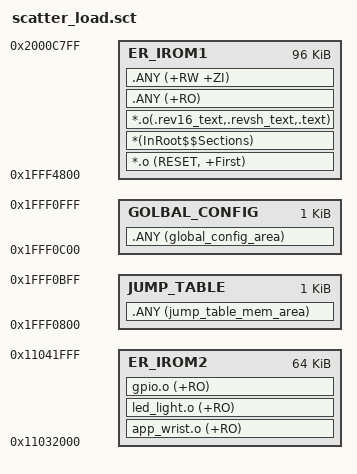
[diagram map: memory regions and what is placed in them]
; *************************************************************
; *** Scatter-Loading Description File generated by uVision ***
; *************************************************************

 LR_IROM1 0x1fff4800 0x00018000 {  ; load region size_region
  ER_IROM1 0x1fff4800 0x00018000  {  ; load address = execution address
   *.o (RESET, +First)
   *(InRoot$$Sections)
   *.o(.rev16_text,.revsh_text,.text)
   .ANY (+RO) 
   .ANY (+RW +ZI)
  }
  
}

LR_IROM2  0x11032000 0x10000 {
  ER_IROM2 0x11032000 0x10000  {
   app_wrist.o (+RO) 
   led_light.o (+RO) 
   gpio.o (+RO)
   ;patch.o(+RO)   //feasible
   ;rf.lib(+RO)    //infeasible
	
  }
} 



LR_IROM3  0x1fff0800 0x00800 {
  JUMP_TABLE 0x1fff0800 0x00400  {
   .ANY (jump_table_mem_area) 
	
  }
  GOLBAL_CONFIG 0x1fff0c00 0x00400  {
   .ANY (global_config_area) 
	
  }  
 } 



